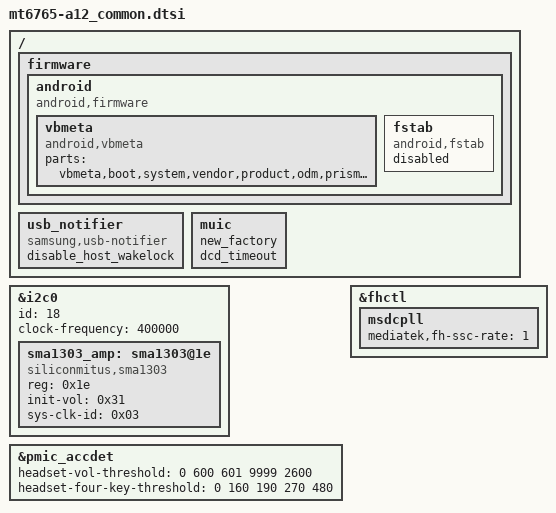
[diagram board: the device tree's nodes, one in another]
/* Generated by Samsung for MTK vendor board 
 * If these files should be changed, then please make a sync with MTK
*/

#include "display_lcd_a12_common.dtsi"
#include "mt6765_input_a12_common.dtsi"
#include "mt6765_a12_grip_00.dtsi"

/* Add Samsung configuration over here */
/ {
	fragment@model {
		target-path = "/";
		__overlay__ {
			firmware {
				android {
					compatible = "android,firmware";
					vbmeta {
						compatible = "android,vbmeta";
						parts = "vbmeta,boot,system,vendor,product,odm,prism,optics,vbmeta_samsung,recovery,lk,tee1";
					};
					fstab {
						compatible = "android,fstab";
						status = "disabled";
					};
				};
			};
			usb_notifier {
				compatible = "samsung,usb-notifier";
				disable_host_wakelock;
			};
			muic {
				new_factory;
				dcd_timeout;
			};
		};
	};
};

&i2c0 {
	status = "okay";
	id = <18>;
	clock-frequency = <400000>;
	#address-cells = <1>;
	#size-cells = <0>;

	sma1303_amp: sma1303@1e {
		#sound-dai-cells = <0>;
		compatible = "siliconmitus,sma1303";
		reg = <0x1e>;
		init-vol = <0x31>;
		sys-clk-id = <0x03>;
		status = "okay";
	};
};

&pmic_accdet {
	/*min_3pole--max_3pole--min_4pole--max_4pole--vol_bias*/
	headset-vol-threshold = <0 600 601 9999 2600>;
	headset-four-key-threshold = <0 160 190 270 480>;
};

&fhctl {
	msdcpll {
		mediatek,fh-ssc-rate = <1>;
	};
};
